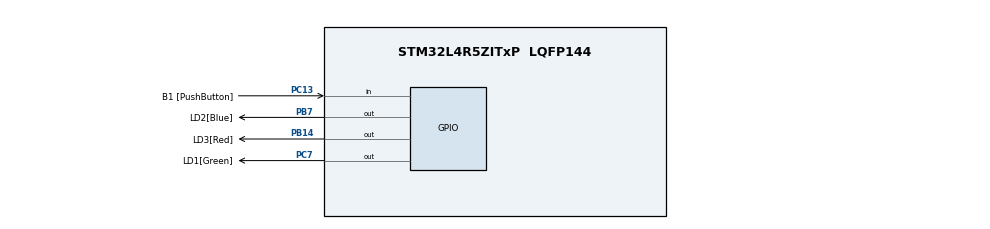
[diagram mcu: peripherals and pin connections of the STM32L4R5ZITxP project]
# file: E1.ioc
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Mcu.Family=STM32L4
Mcu.Name=STM32L4R5ZITxP
Mcu.Package=LQFP144
NVIC.PriorityGroup=NVIC_PRIORITYGROUP_4
PB14.GPIO_Label=LD3[Red]
PB14.PinState=GPIO_PIN_SET
PB14.Signal=GPIO_Output
PB7.GPIO_Label=LD2[Blue]
PB7.PinState=GPIO_PIN_SET
PB7.Signal=GPIO_Output
PC13.GPIO_Label=B1 [PushButton]
PC13.Signal=GPIO_Input
PC7.GPIO_Label=LD1[Green]
PC7.PinState=GPIO_PIN_SET
PC7.Signal=GPIO_Output
ProjectManager.HeapSize=0x200
ProjectManager.StackSize=0x400
ProjectManager.TargetToolchain=STM32CubeIDE
RCC.HSE_VALUE=8000000
RCC.HSI48_VALUE=48000000
RCC.HSI_VALUE=16000000
RCC.LSE_VALUE=32768
RCC.MSI_VALUE=4000000
RCC.VCOOutputFreq_Value=32000000
board=custom

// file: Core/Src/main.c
/* USER CODE BEGIN Header */
/**
  ******************************************************************************
  * @file           : main.c
  * @brief          : Main program body
  ******************************************************************************
  * @attention
  *
  * Copyright (c) 2022 STMicroelectronics.
  * All rights reserved.
  *
  * This software is licensed under terms that can be found in the LICENSE file
  * in the root directory of this software component.
  * If no LICENSE file comes with this software, it is provided AS-IS.
  *
  ******************************************************************************
  */
/* USER CODE END Header */
#include "main.h"
#include <stdint.h>
#include <stdbool.h>

#define EXECUTION_MODE_DEP = 1
#define EXECUTION_MODE_INDEP = 0

 typedef uint32_t tick_t;
  // For the data type to be executed, the stdint.h library must be included.

  typedef bool bool_t;

  // For the data type to be executed, the stdbool.h library must be included.

  typedef struct
  {
  	tick_t startTime;
  	tick_t duration;
  	bool_t running;

  } delay_t;

  void delayInit(delay_t *delay, tick_t duration);
  bool_t delayRead(delay_t *delay);
  void delayWrite(delay_t *delay, tick_t duration);
  //* Implementation of delayInit.-
  //* Initialize a delay object using the HAL_GetTick() function and setting
  // the flag running in false.

  void delayInit(delay_t *delay, tick_t duration) {

  	// We validate that duration has an allowed value

  	if (duration < 0) {
  		return;
  	}

  	delay->duration = duration;
  	delay->startTime = HAL_GetTick();
  	delay->running = false;
  	// Implementation of delayRead.- Validates if the time has elapsed with
  	// respect to the initial saved moment.
  	// @Parameters.
  	// delay - Direction of memory where is defined the delay.
  	// true. The time surpassed the duration.
  	// false - The time doesn't surpassed the setting duration.
  }

  bool_t delayRead(delay_t *delay) {

  	if (delay->running) {

  		if (HAL_GetTick() >= (delay->startTime + delay->duration)) {
  			delay->running = false;
  			return true;
  		} else {
  			return false;
  		}
  	} else {
  		delay->startTime = HAL_GetTick();
  		delay->running = true;
  		return false;
  	}

  }

  //Implementation of delayWrite.- Allows you to change the duration
   // value of an existing delay object.
   //
   // @params:
   //  delay - direction of memory where where is defined the delay
   //  duration - Value of the duration.

  void delayWrite(delay_t *delay, tick_t duration)
  {

  // we validate the parameters
  	if (duration < 0)
  		return;

  	delay->duration = duration;
  }

void SystemClock_Config(void);
static void MX_GPIO_Init(void);

const tick_t LED_1_TIME = 100;
const tick_t LED_2_TIME = 500;
const tick_t LED_3_TIME = 1000;

int main(void)
{

  /* MCU Configuration--------------------------------------------------------*/

  /* Reset of all peripherals, Initializes the Flash interface and the Systick. */
  HAL_Init();

  SystemClock_Config();

  HAL_GPIO_WritePin(LD1_GPIO_Port, LD1_Pin, GPIO_PIN_SET);
  HAL_GPIO_WritePin(LD2_GPIO_Port, LD2_Pin, GPIO_PIN_SET);
  HAL_GPIO_WritePin(LD3_GPIO_Port, LD3_Pin, GPIO_PIN_SET);

  	delay_t delay3;
  	delay_t delay2;
  	delay_t delay1;

  	// Power off the three leds.
  HAL_GPIO_WritePin(LD1_GPIO_Port, LD1_Pin, GPIO_PIN_RESET);
  HAL_GPIO_WritePin(LD2_GPIO_Port, LD2_Pin, GPIO_PIN_RESET);
  HAL_GPIO_WritePin(LD3_GPIO_Port, LD3_Pin, GPIO_PIN_RESET);

  	delayInit(&delay3, LED_3_TIME);
  	delayInit(&delay2, LED_2_TIME);
  	delayInit(&delay1, LED_1_TIME);

  /* Configure the system clock */

  /* Initialize all configured peripherals */
  MX_GPIO_Init();

  /* Infinite loop */
  /* USER CODE BEGIN WHILE */

  while (1)
  {
	  if (delayRead(&delay3))
	       {
		  HAL_GPIO_WritePin(LD3_GPIO_Port, LD3_Pin, GPIO_PIN_SET);

	  		}
	  		if (delayRead(&delay2)) {
	  	  HAL_GPIO_WritePin(LD2_GPIO_Port, LD2_Pin, GPIO_PIN_SET);
	  		}
	  		if (delayRead(&delay1)) {
	  	  HAL_GPIO_WritePin(LD1_GPIO_Port, LD1_Pin, GPIO_PIN_SET);
	  		}

  }

   //Read the status to the GPIO Button  pin
   //check if this high or low

    /* USER CODE END WHILE */

}

void SystemClock_Config(void)
{
  RCC_OscInitTypeDef RCC_OscInitStruct = {0};
  RCC_ClkInitTypeDef RCC_ClkInitStruct = {0};

  /** Configure the main internal regulator output voltage
  */
  if (HAL_PWREx_ControlVoltageScaling(PWR_REGULATOR_VOLTAGE_SCALE1) != HAL_OK)
  {
    Error_Handler();
  }

  /** Initializes the RCC Oscillators according to the specified parameters
  * in the RCC_OscInitTypeDef structure.
  */
  RCC_OscInitStruct.OscillatorType = RCC_OSCILLATORTYPE_MSI;
  RCC_OscInitStruct.MSIState = RCC_MSI_ON;
  RCC_OscInitStruct.MSICalibrationValue = 0;
  RCC_OscInitStruct.MSIClockRange = RCC_MSIRANGE_6;
  RCC_OscInitStruct.PLL.PLLState = RCC_PLL_NONE;
  if (HAL_RCC_OscConfig(&RCC_OscInitStruct) != HAL_OK)
  {
    Error_Handler();
  }

  /** Initializes the CPU, AHB and APB buses clocks
  */
  RCC_ClkInitStruct.ClockType = RCC_CLOCKTYPE_HCLK|RCC_CLOCKTYPE_SYSCLK
                              |RCC_CLOCKTYPE_PCLK1|RCC_CLOCKTYPE_PCLK2;
  RCC_ClkInitStruct.SYSCLKSource = RCC_SYSCLKSOURCE_MSI;
  RCC_ClkInitStruct.AHBCLKDivider = RCC_SYSCLK_DIV1;
  RCC_ClkInitStruct.APB1CLKDivider = RCC_HCLK_DIV1;
  RCC_ClkInitStruct.APB2CLKDivider = RCC_HCLK_DIV1;

  if (HAL_RCC_ClockConfig(&RCC_ClkInitStruct, FLASH_LATENCY_0) != HAL_OK)
  {
    Error_Handler();
  }
}

static void MX_GPIO_Init(void)
{
  GPIO_InitTypeDef GPIO_InitStruct = {0};

  /* GPIO Ports Clock Enable */
  __HAL_RCC_GPIOC_CLK_ENABLE();
  __HAL_RCC_GPIOB_CLK_ENABLE();

  /*Configure GPIO pin Output Level */
  HAL_GPIO_WritePin(GPIOB, LD3_Pin|LD2_Pin, GPIO_PIN_SET);

  /*Configure GPIO pin Output Level */
  HAL_GPIO_WritePin(LD1_GPIO_Port, LD1_Pin, GPIO_PIN_SET);

  /*Configure GPIO pin : B1_Pin */
  GPIO_InitStruct.Pin = B1_Pin;
  GPIO_InitStruct.Mode = GPIO_MODE_INPUT;
  GPIO_InitStruct.Pull = GPIO_NOPULL;
  HAL_GPIO_Init(B1_GPIO_Port, &GPIO_InitStruct);

  /*Configure GPIO pins : LD3_Pin LD2_Pin */
  GPIO_InitStruct.Pin = LD3_Pin|LD2_Pin;
  GPIO_InitStruct.Mode = GPIO_MODE_OUTPUT_PP;
  GPIO_InitStruct.Pull = GPIO_NOPULL;
  GPIO_InitStruct.Speed = GPIO_SPEED_FREQ_LOW;
  HAL_GPIO_Init(GPIOB, &GPIO_InitStruct);

  /*Configure GPIO pin : LD1_Pin */
  GPIO_InitStruct.Pin = LD1_Pin;
  GPIO_InitStruct.Mode = GPIO_MODE_OUTPUT_PP;
  GPIO_InitStruct.Pull = GPIO_NOPULL;
  GPIO_InitStruct.Speed = GPIO_SPEED_FREQ_LOW;
  HAL_GPIO_Init(LD1_GPIO_Port, &GPIO_InitStruct);

}

void Error_Handler(void)
{
  __disable_irq();
  while (1)
  {
  }
}
